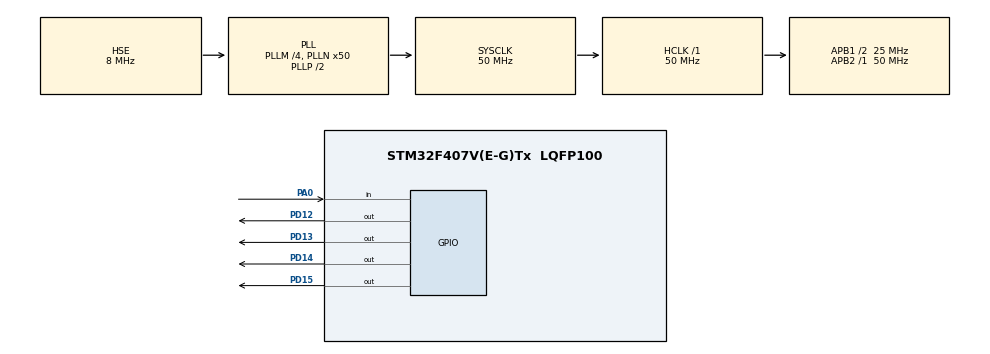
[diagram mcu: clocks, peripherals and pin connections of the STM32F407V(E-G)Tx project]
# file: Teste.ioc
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IWDG.Prescaler=IWDG_PRESCALER_32
IWDG.Reload=1000
Mcu.Family=STM32F4
Mcu.Name=STM32F407V(E-G)Tx
Mcu.Package=LQFP100
NVIC.PriorityGroup=NVIC_PRIORITYGROUP_4
PA0-WKUP.GPIO_PuPd=GPIO_PULLDOWN
PA0-WKUP.Signal=GPIO_Input
PA13.Mode=Serial_Wire
PA13.Signal=SYS_JTMS-SWDIO
PA14.Mode=Serial_Wire
PA14.Signal=SYS_JTCK-SWCLK
PC14-OSC32_IN.Mode=LSE-External-Oscillator
PC14-OSC32_IN.Signal=RCC_OSC32_IN
PC15-OSC32_OUT.Mode=LSE-External-Oscillator
PC15-OSC32_OUT.Signal=RCC_OSC32_OUT
PD12.GPIO_PuPd=GPIO_PULLUP
PD12.Signal=GPIO_Output
PD13.Signal=GPIO_Output
PD14.Signal=GPIO_Output
PD15.Signal=GPIO_Output
PH0-OSC_IN.Mode=HSE-External-Oscillator
PH0-OSC_IN.Signal=RCC_OSC_IN
PH1-OSC_OUT.Mode=HSE-External-Oscillator
PH1-OSC_OUT.Signal=RCC_OSC_OUT
ProjectManager.HeapSize=0x200
ProjectManager.StackSize=0x400
ProjectManager.TargetToolchain=STM32CubeIDE
RCC.48MHZClocksFreq_Value=25000000
RCC.AHBFreq_Value=50000000
RCC.APB1CLKDivider=RCC_HCLK_DIV2
RCC.APB1Freq_Value=25000000
RCC.APB1TimFreq_Value=50000000
RCC.APB2Freq_Value=50000000
RCC.APB2TimFreq_Value=50000000
RCC.CortexFreq_Value=50000000
RCC.HCLKFreq_Value=50000000
RCC.HSE_VALUE=8000000
RCC.HSI_VALUE=16000000
RCC.PLLM=4
RCC.PLLN=50
RCC.PLLSourceVirtual=RCC_PLLSOURCE_HSE
RCC.SYSCLKFreq_VALUE=50000000
RCC.SYSCLKSource=RCC_SYSCLKSOURCE_PLLCLK
RCC.VCOOutputFreq_Value=100000000
TIM1.Period=10000
TIM1.Prescaler=50
VP_IWDG_VS_IWDG.Mode=IWDG_Activate
VP_TIM1_VS_ClockSourceINT.Mode=Internal
board=custom

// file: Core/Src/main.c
/* USER CODE BEGIN Header */
/**
  ******************************************************************************
  * @file           : main.c
  * @brief          : Main program body
  ******************************************************************************
  * @attention
  *
  * Copyright (c) 2025 STMicroelectronics.
  * All rights reserved.
  *
  * This software is licensed under terms that can be found in the LICENSE file
  * in the root directory of this software component.
  * If no LICENSE file comes with this software, it is provided AS-IS.
  *
  ******************************************************************************
  */
/* USER CODE END Header */
#include "main.h"
#include "iwdg.h"
#include "tim.h"
#include "gpio.h"

void SystemClock_Config(void);

int main(void)
{

  /* MCU Configuration--------------------------------------------------------*/

  /* Reset of all peripherals, Initializes the Flash interface and the Systick. */
  HAL_Init();

  /* Configure the system clock */
  SystemClock_Config();

  /* Initialize all configured peripherals */
  MX_GPIO_Init();
  MX_TIM1_Init();
  MX_IWDG_Init();
  /* USER CODE BEGIN 2 */
  if(__HAL_RCC_GET_FLAG(RCC_FLAG_IWDGRST) != RESET)
  {
	  __HAL_RCC_CLEAR_RESET_FLAGS();
	  HAL_GPIO_WritePin(GPIOD, GPIO_PIN_12, 1);
  }
  else{
	  HAL_GPIO_WritePin(GPIOD, GPIO_PIN_14, 1);
  }

//HAL_TIM_PWM_Start(&htim4,TIM_CHANNEL_1);
//HAL_TIM_PWM_Start(&htim4,TIM_CHANNEL_2);
//HAL_TIM_PWM_Start(&htim4,TIM_CHANNEL_3);
//HAL_TIM_PWM_Start(&htim4,TIM_CHANNEL_4);

//start do watchdog
HAL_IWDG_Init(&hiwdg);
  /* USER CODE END 2 */

  /* Infinite loop */
  /* USER CODE BEGIN WHILE */
  while (1)
  {
	  HAL_IWDG_Refresh(&hiwdg);

	  if(HAL_GPIO_ReadPin(GPIOA, GPIO_PIN_0) == GPIO_PIN_SET)
	  {
	HAL_GPIO_TogglePin(GPIOD, GPIO_PIN_12);

	  	  HAL_Delay(100);
	  	  while(1);
	  }
	  //HAL_GPIO_TogglePin(GPIOD, GPIO_PIN_12);
	 // HAL_GPIO_TogglePin(GPIOD, GPIO_PIN_13);
	 // HAL_Delay(100);
    /* USER CODE END WHILE */

  }
}

void SystemClock_Config(void)
{
  RCC_OscInitTypeDef RCC_OscInitStruct = {0};
  RCC_ClkInitTypeDef RCC_ClkInitStruct = {0};

  /** Configure the main internal regulator output voltage
  */
  __HAL_RCC_PWR_CLK_ENABLE();
  __HAL_PWR_VOLTAGESCALING_CONFIG(PWR_REGULATOR_VOLTAGE_SCALE1);

  /** Initializes the RCC Oscillators according to the specified parameters
  * in the RCC_OscInitTypeDef structure.
  */
  RCC_OscInitStruct.OscillatorType = RCC_OSCILLATORTYPE_LSI|RCC_OSCILLATORTYPE_HSE;
  RCC_OscInitStruct.HSEState = RCC_HSE_ON;
  RCC_OscInitStruct.LSIState = RCC_LSI_ON;
  RCC_OscInitStruct.PLL.PLLState = RCC_PLL_ON;
  RCC_OscInitStruct.PLL.PLLSource = RCC_PLLSOURCE_HSE;
  RCC_OscInitStruct.PLL.PLLM = 4;
  RCC_OscInitStruct.PLL.PLLN = 50;
  RCC_OscInitStruct.PLL.PLLP = RCC_PLLP_DIV2;
  RCC_OscInitStruct.PLL.PLLQ = 4;
  if (HAL_RCC_OscConfig(&RCC_OscInitStruct) != HAL_OK)
  {
    Error_Handler();
  }

  /** Initializes the CPU, AHB and APB buses clocks
  */
  RCC_ClkInitStruct.ClockType = RCC_CLOCKTYPE_HCLK|RCC_CLOCKTYPE_SYSCLK
                              |RCC_CLOCKTYPE_PCLK1|RCC_CLOCKTYPE_PCLK2;
  RCC_ClkInitStruct.SYSCLKSource = RCC_SYSCLKSOURCE_PLLCLK;
  RCC_ClkInitStruct.AHBCLKDivider = RCC_SYSCLK_DIV1;
  RCC_ClkInitStruct.APB1CLKDivider = RCC_HCLK_DIV2;
  RCC_ClkInitStruct.APB2CLKDivider = RCC_HCLK_DIV1;

  if (HAL_RCC_ClockConfig(&RCC_ClkInitStruct, FLASH_LATENCY_1) != HAL_OK)
  {
    Error_Handler();
  }
}

void Error_Handler(void)
{
  __disable_irq();
  while (1)
  {
  }
}
